# pwrseq_me10 register map
Registers are access not given, no defined reset value unless marked. A register's access mark holds for its fields unless they carry their own. Offsets are from the block's base; lines under a group give offsets from that group; [hi:lo] are bit positions; {n}, {i} and the like mark numbered series; 'fields as' and 'values as' point back to an identical list; <NAME> marks a mode.

## Memory map
0x40006800 PWRSEQ size 0x400 — Power Sequencer / Low Power Control Register.

## PWRSEQ — Power Sequencer / Low Power Control Register.
Base 0x40006800
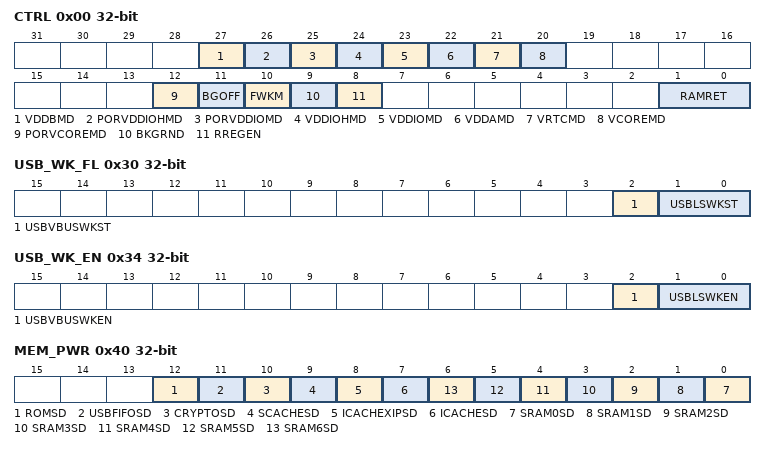
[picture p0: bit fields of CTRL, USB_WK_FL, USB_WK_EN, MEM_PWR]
0x00 CTRL — Low Power Control Register.
  [27] VDDBMD — VDDB Power-On Reset Monitor Disable. This bit controls the Power-On Reset monitor on VDDB supply in all operating mods.
    0=en (Enabled.); 1=dis (Disabled.)
  [26] PORVDDIOHMD — VFDDIOH Monitor Disable. This bit controls the power monitor of the Analog Supply in all operating modes.
    0=en (Enable if Bandgap is ON(default)); 1=dis (Disabled.)
  [25] PORVDDIOMD — VFDDIOH Monitor Disable. This bit controls the power monitor of the Analog Supply in all operating modes.
    0=en (Enable if Bandgap is ON(default)); 1=dis (Disabled.)
  [24] VDDIOHMD — VFDDIOH Monitor Disable. This bit controls the power monitor of the Analog Supply in all operating modes.
    0=en (Enable if Bandgap is ON(default)); 1=dis (Disabled.)
  [23] VDDIOMD — VDDIO Monitor Disable. This bit controls the power monitor of the Analog Supply in all operating modes.
    0=en (Enable if Bandgap is ON(default)); 1=dis (Disabled.)
  [22] VDDAMD — VDDA Monitor Disable. This bit controls the power monitor of the Analog Supply in all operating modes.
    0=en (Enable if Bandgap is ON(default)); 1=dis (Disabled.)
  [21] VRTCMD — VRTC Monitor Disable. This bit controls the power monitor on the Always-On Supply in all operating modes.
    0=en (Enable if Bandgap is ON(default)); 1=dis (Disabled.)
  [20] VCOREMD — VDDC(Vcore) Monitor Disable. This bit controls the power monitor on the VCore supply in all operating modes.
    0=en (Enable if Bandgap is ON(default)); 1=dis (Disabled.)
  [12] PORVCOREMD — VCORE POR Monitor for DEEPSLEEP and BACKUP Disable Write 1 to disable the power failure monitor. With the power failure monitor enabled, if the voltage drops below the trigger voltage the device enters a Power-On Reset.
    0=en (Enable if Bandgap is ON(default)); 1=dis (Disabled.)
  [11] BGOFF — Bandgap OFF. This controls the System Bandgap in DeepSleep mode.
    0=on (Bandgap is always ON.); 1=off (Bandgap is OFF in DeepSleep mode(default).)
  [10] FWKM — Fast Wake-Up Mode. This bit enables fast wake-up from DeepSleep mode. (5uS typical).
    0=dis (Disabled.); 1=en (Enabled.)
  [9] BKGRND — Background Mode Enable. This bit allows low-power background mode operations, while the CPU is in DeepSleep.
    0=dis (Disabled.); 1=en (Enabled.)
  [8] RREGEN — Backup Mode RAM Retention Regulator Enable
    0=dis (Disabled.); 1=en (Enabled.)
  [1:0] RAMRET — System RAM retention in BACKUP mode. These two bits are used in conjuction with RREGEN bit.
    0=dis (Disable Ram Retention.); 1=en1 (Enable System RAM 0 retention.); 2=en2 (Enable System RAM 0 and 1 retention.); 3=en3 (Enable System RAM 0 and 1 retention, if RREGEN=0, Enable all System RAM retention.)
0x04 GPIO0_WK_FL — Low Power I/O Wakeup Status Register 0. This register indicates the low power wakeup status for GPIO0.
  [31:0] WAKEST — Wakeup IRQ flags (write ones to clear). One or more of these bits will be set when the corresponding dedicated GPIO pin(s) transition(s) from low to high or high to low. If GPIO wakeup source is selected, using PM.GPIOWKEN register, and the corresponding bit is also selected in LPWKEN register, an interrupt will be gnerated to wake up the CPU from a low power mode.
0x08 GPIO0_WK_EN — Low Power I/O Wakeup Enable Register 0. This register enables low power wakeup functionality for GPIO0.
  [31:0] WAKEEN — Enable wakeup. These bits allow wakeup from the corresponding GPIO pin(s) on transition(s) from low to high or high to low when PM.GPIOWKEN is set. Wakeup status is indicated in PPWKST register.
0x0C GPIO1_WK_FL — Low Power I/O Wakeup Status Register 1. This register indicates the low power wakeup status for GPIO1.
  fields as GPIO0_WK_FL
0x10 GPIO1_WK_EN — Low Power I/O Wakeup Enable Register 1. This register enables low power wakeup functionality for GPIO1.
  fields as GPIO0_WK_EN
0x14 GPIO2_WK_FL — Low Power I/O Wakeup Status Register 0. This register indicates the low power wakeup status for GPIO2.
  fields as GPIO0_WK_FL
0x18 GPIO2_WK_EN — Low Power I/O Wakeup Enable Register 0. This register enables low power wakeup functionality for GPIO0.
  fields as GPIO0_WK_EN
0x1C GPIO3_WK_FL — Low Power I/O Wakeup Status Register 0. This register indicates the low power wakeup status for GPIO3.
  [9:0] WAKEST — Wakeup IRQ flags (write ones to clear). One or more of these bits will be set when the corresponding dedicated GPIO pin(s) transition(s) from low to high or high to low. If GPIO wakeup source is selected, using PM.GPIOWKEN register, and the corresponding bit is also selected in LPWKEN register, an interrupt will be gnerated to wake up the CPU from a low power mode.
0x20 GPIO3_WK_EN — Low Power I/O Wakeup Enable Register 0. This register enables low power wakeup functionality for GPIO3.
  [9:0] WAKEEN — Enable wakeup. These bits allow wakeup from the corresponding GPIO pin(s) on transition(s) from low to high or high to low when PM.GPIOWKEN is set. Wakeup status is indicated in PPWKST register.
0x30 USB_WK_FL — Low Power Peripheral Wakeup Status Register.
  [2] USBVBUSWKST — USB VBUS Detect Wakeup Flag (write one to clear). This bit will be set when the USB power supply is powered on or powered off.
    0=Normal operation; 1=stchng (Disabled.)
  [1:0] USBLSWKST — USB UTMI Linestate Detect Wakeup Flag(write one to clear). One or both of these bits will be set when the USB bus activity causes the linestate to change and the device to wake while USB wakeup is enabled using PMLUSBWKEN.
    0=D Plus line state change; 1=D Minus line state change
0x34 USB_WK_EN — Low Power Peripheral Wakeup Enable Register.
  [2] USBVBUSWKEN — USB VBUS Detect Wakeup Enable. This bit allows wakeup from the USB power supply on or off status.
    0=dis (Disable.); 1=en (Enabled.)
  [1:0] USBLSWKEN — USB UTMI Linestate Detect Wakeup Enable. These bits allow wakeup from the corresponding USB linestate signal(s) on transition(s) from low to high or high to low when PM.USBWKEN is set.
    0=dis (Disable.); 3=en (Enabled.)
0x40 MEM_PWR — Low Power Memory Shutdown Control.
  [all] fields
    0=Normal Operating Mode; 1=Shutdown Mode
  [12] ROMSD — ROM Shut Down.
  [11] USBFIFOSD — USB FIFO Shut Down.
  [10] CRYPTOSD — Crypto MAA RAM Shut Down.
  [9] SCACHESD — System Cache RAM Shut Down.
  [8] ICACHEXIPSD — XiP Instruction Cache RAM Shut Down.
  [7] ICACHESD — Instruction Cache RAM Shut Down.
  [n] SRAM{n}SD (n=0..6) — System RAM block {n} Shut Down.
